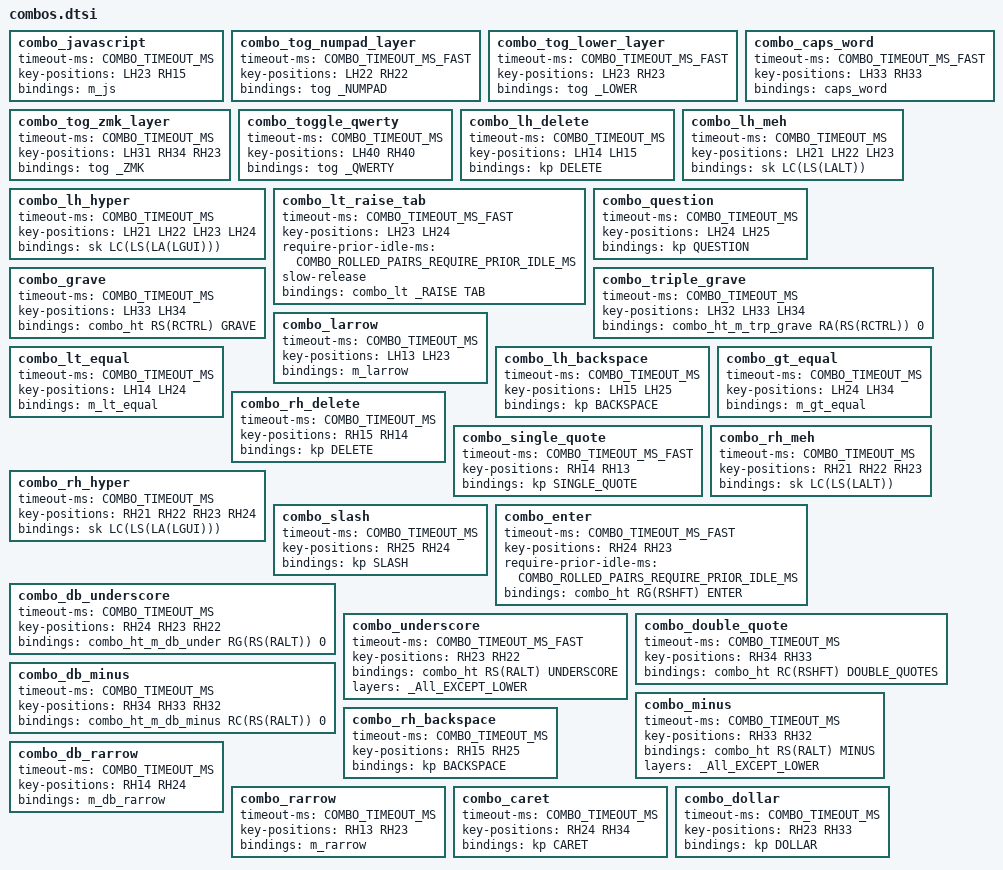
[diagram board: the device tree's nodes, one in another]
// Combo Definitions
// https://zmk.dev/docs/features/combos
// https://zmk.dev/docs/config/combos

#include "key_positions.dtsi"
#include "layers.dtsi"
#include "macros.dtsi"

#define COMBO_TIMEOUT_MS_FAST 30
#define COMBO_TIMEOUT_MS 70
#define COMBO_ROLLED_PAIRS_REQUIRE_PRIOR_IDLE_MS 100

// Both Hands
combo_javascript {
  timeout-ms = <COMBO_TIMEOUT_MS>;
  key-positions = <LH23 RH15>; // S & J (D & Y)
  bindings = <&m_js>;
};
combo_tog_numpad_layer {
  timeout-ms = <COMBO_TIMEOUT_MS_FAST>;
  key-positions = <LH22 RH22>; // R & I (S & L)
  bindings = <&tog _NUMPAD>;
};
combo_tog_lower_layer {
  timeout-ms = <COMBO_TIMEOUT_MS_FAST>;
  key-positions = <LH23 RH23>; // S & E (D & K)
  bindings = <&tog _LOWER>;
};
combo_caps_word {
  timeout-ms = <COMBO_TIMEOUT_MS_FAST>;
  key-positions = <LH33 RH33>; // C & COMMA (C & COMMA)
  bindings = <&caps_word>;
};
combo_tog_zmk_layer {
  timeout-ms = <COMBO_TIMEOUT_MS>;
  key-positions = <LH31 RH34 RH23>; // Z, M, & K (Z, H, & E)
  bindings = <&tog _ZMK>;
};
combo_toggle_qwerty {
  timeout-ms = <COMBO_TIMEOUT_MS>;
  key-positions = <LH40 RH40>; // Bottom Left & Bottom Right Keys
  bindings = <&tog _QWERTY>;
};

// Left Hand
// Horizontal Combos
// Top Row
combo_lh_delete {
  timeout-ms = <COMBO_TIMEOUT_MS>;
  key-positions = <LH14 LH15>; // P & B (R & T)
  bindings = <&kp DELETE>;
};
// Home Row
combo_lh_meh {
  timeout-ms = <COMBO_TIMEOUT_MS>;
  key-positions = <LH21 LH22 LH23>; // A, R, & S (A, S, & D)
  bindings = <&sk LC(LS(LALT))>;
};
combo_lh_hyper {
  timeout-ms = <COMBO_TIMEOUT_MS>;
  key-positions = <LH21 LH22 LH23 LH24>; // A, R, S, & T (A, S, D, & F)
  bindings = <&sk LC(LS(LA(LGUI)))>;
};
combo_lt_raise_tab {
  timeout-ms = <COMBO_TIMEOUT_MS_FAST>;
  key-positions = <LH23 LH24>; // S & T (D & F)
  require-prior-idle-ms = <COMBO_ROLLED_PAIRS_REQUIRE_PRIOR_IDLE_MS>;
  slow-release;
  bindings = <&combo_lt _RAISE TAB>;
};
combo_question {
  timeout-ms = <COMBO_TIMEOUT_MS>;
  key-positions = <LH24 LH25>; // T & G (F & G)
  bindings = <&kp QUESTION>;
};
// Bottom Row
combo_triple_grave {
  timeout-ms = <COMBO_TIMEOUT_MS>;
  key-positions = <LH32 LH33 LH34>; // X, C, & D (X, C, & V)
  // https://zmk.dev/docs/behaviors/hold-tap#using-different-behavior-types-with-hold-taps
  // You need a dummy parameter here, see link above.
  bindings = <&combo_ht_m_trp_grave RA(RS(RCTRL)) 0>;
};
combo_grave {
  timeout-ms = <COMBO_TIMEOUT_MS>;
  key-positions = <LH33 LH34>; // C & D (C & V)
  bindings = <&combo_ht RS(RCTRL) GRAVE>;
};

// Vertical Combos
// Top + Home Rows
combo_larrow {
  timeout-ms = <COMBO_TIMEOUT_MS>;
  key-positions = <LH13 LH23>; // F & S (E & D)
  bindings = <&m_larrow>;
};
combo_lt_equal {
  timeout-ms = <COMBO_TIMEOUT_MS>;
  key-positions = <LH14 LH24>; // P & T (R & F)
  bindings = <&m_lt_equal>;
};
combo_lh_backspace {
  timeout-ms = <COMBO_TIMEOUT_MS>;
  key-positions = <LH15 LH25>; // B & G (T & G)
  bindings = <&kp BACKSPACE>;
};
// Home + Bottom Rows
combo_gt_equal {
  timeout-ms = <COMBO_TIMEOUT_MS>;
  key-positions = <LH24 LH34>; // T & D (F & V)
  bindings = <&m_gt_equal>;
};


// Right Hand
// Horizontal Combos
// Top Row
combo_rh_delete {
  timeout-ms = <COMBO_TIMEOUT_MS>;
  key-positions = <RH15 RH14>; // J & L (Y & U)
  bindings = <&kp DELETE>;
};
combo_single_quote {
  timeout-ms = <COMBO_TIMEOUT_MS_FAST>;
  key-positions = <RH14 RH13>; // L & U (U & I)
  bindings = <&kp SINGLE_QUOTE>;
};
// Home Row
combo_rh_meh {
  timeout-ms = <COMBO_TIMEOUT_MS>;
  key-positions = <RH21 RH22 RH23>; // E, I, & O (K, L, & SEMI)
  bindings = <&sk LC(LS(LALT))>;
};
combo_rh_hyper {
  timeout-ms = <COMBO_TIMEOUT_MS>;
  key-positions = <RH21 RH22 RH23 RH24>; // N, E, I, & O (J, K, L, & SEMI)
  bindings = <&sk LC(LS(LA(LGUI)))>;
};
combo_slash {
  timeout-ms = <COMBO_TIMEOUT_MS>;
  key-positions = <RH25 RH24>; // M & N (H & J)
  bindings = <&kp SLASH>;
};
combo_enter {
  timeout-ms = <COMBO_TIMEOUT_MS_FAST>;
  key-positions = <RH24 RH23>; // N & E (J & K)
  require-prior-idle-ms = <COMBO_ROLLED_PAIRS_REQUIRE_PRIOR_IDLE_MS>;
  bindings = <&combo_ht RG(RSHFT) ENTER>;
};
combo_db_underscore {
  timeout-ms = <COMBO_TIMEOUT_MS>;
  key-positions = <RH24 RH23 RH22>; // N, E, & I (J, K & L)
  // See note above regarding dummy parameter.
  bindings = <&combo_ht_m_db_under RG(RS(RALT)) 0>;
};
combo_underscore {
  timeout-ms = <COMBO_TIMEOUT_MS_FAST>;
  key-positions = <RH23 RH22>; // E & I (K & L)
  bindings = <&combo_ht RS(RALT) UNDERSCORE>;
  layers  = <_All_EXCEPT_LOWER>; // all but _LOWER, for fast () rolls
};
// Bottom Row
combo_double_quote {
  timeout-ms = <COMBO_TIMEOUT_MS>;
  key-positions = <RH34 RH33>; // H & COMMA (M & COMMA)
  bindings = <&combo_ht RC(RSHFT) DOUBLE_QUOTES>;
};
combo_db_minus {
  timeout-ms = <COMBO_TIMEOUT_MS>;
  key-positions = <RH34 RH33 RH32>; // H, COMMA, & DOT (M, COMMA, & DOT)
  // See note above regarding dummy parameter.
  bindings = <&combo_ht_m_db_minus RC(RS(RALT)) 0>;
};
combo_minus {
  timeout-ms = <COMBO_TIMEOUT_MS>;
  key-positions = <RH33 RH32>; // COMMA & DOT (COMMA & DOT)
  bindings = <&combo_ht RS(RALT) MINUS>;
  layers  = <_All_EXCEPT_LOWER>; // all but _LOWER, for fast {} rolls
};

// Vertical Combos
// Top + Home Rows
combo_rh_backspace {
  timeout-ms = <COMBO_TIMEOUT_MS>;
  key-positions = <RH15 RH25>; // J & M (Y & H)
  bindings = <&kp BACKSPACE>;
};
combo_db_rarrow {
  timeout-ms = <COMBO_TIMEOUT_MS>;
  key-positions = <RH14 RH24>; // L & N (U & J)
  bindings = <&m_db_rarrow>;
};
combo_rarrow {
  timeout-ms = <COMBO_TIMEOUT_MS>;
  key-positions = <RH13 RH23>; // U & E (I & K)
  bindings = <&m_rarrow>;
};
// Home + Bottom Rows
combo_caret {
  timeout-ms = <COMBO_TIMEOUT_MS>;
  key-positions = <RH24 RH34>; // N & H (J & M)
  bindings = <&kp CARET>;
};
combo_dollar {
  timeout-ms = <COMBO_TIMEOUT_MS>;
  key-positions = <RH23 RH33>; // E & COMMA (K & COMMA)
  bindings = <&kp DOLLAR>;
};
